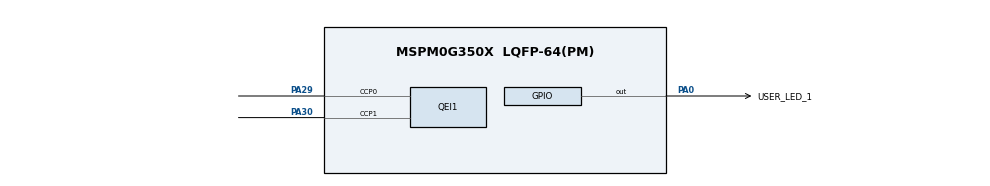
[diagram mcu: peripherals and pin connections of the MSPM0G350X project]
// @cliArgs --device "MSPM0G350X" --package "LQFP-64(PM)" --part "Default"
// @cliArgs --board /ti/boards/LP_MSPM0G3507 --rtos nortos

/**
 * Import the modules used in this configuration.
 */
const GPIO   = scripting.addModule("/ti/driverlib/GPIO", {}, false);
const GPIO1  = GPIO.addInstance();
const QEI    = scripting.addModule("/ti/driverlib/QEI", {}, false);
const QEI1   = QEI.addInstance();
const SYSCTL = scripting.addModule("/ti/driverlib/SYSCTL");

/**
 * Write custom configuration values to the imported modules.
 */
GPIO1.$name                          = "GPIO_LEDS";
GPIO1.associatedPins[0].$name        = "USER_LED_1";
GPIO1.associatedPins[0].initialValue = "SET";
GPIO1.associatedPins[0].pin.$assign  = "PA0";

const Board = scripting.addModule("/ti/driverlib/Board", {}, false);

QEI1.$name                      = "QEI_0";
QEI1.interrupts                 = ["DC_EVENT"];
QEI1.peripheral.$assign         = "TIMG8";
QEI1.peripheral.ccp0Pin.$assign = "PA29";
QEI1.peripheral.ccp1Pin.$assign = "PA30";

SYSCTL.EXCLKSource = "LFCLK";
SYSCTL.forceDefaultClkConfig = true;
SYSCTL.clockTreeEn  = true;
